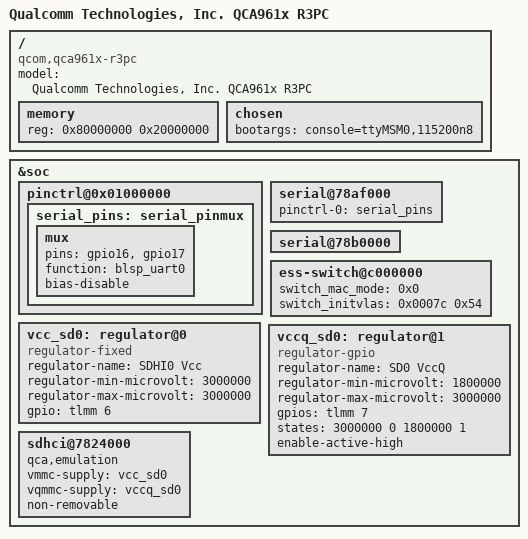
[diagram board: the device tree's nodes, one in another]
/* Copyright (c) 2014, The Linux Foundation. All rights reserved.
 *
 * This program is free software; you can redistribute it and/or modify
 * it under the terms of the GNU General Public License version 2 and
 * only version 2 as published by the Free Software Foundation.
 *
 * This program is distributed in the hope that it will be useful,
 * but WITHOUT ANY WARRANTY; without even the implied warranty of
 * MERCHANTABILITY or FITNESS FOR A PARTICULAR PURPOSE.  See the
 * GNU General Public License for more details.
 */

#include "qcom-qca961x.dtsi"
#include "qcom-qca961x-display.dtsi"
#include "qpic-panel-ili-qvga.dtsi"
#include "qcom-qca961x-hsuart.dtsi"

/ {
	model = "Qualcomm Technologies, Inc. QCA961x R3PC";
	compatible = "qcom,qca961x-r3pc", "qcom,qca961x";

	memory {
		device_type = "memory";
		reg = <0x80000000 0x20000000>; /* 512MB */
	};

	chosen {
		bootargs = "console=ttyMSM0,115200n8";
	};

};
	&soc {
		pinctrl@0x01000000 {
			serial_pins: serial_pinmux {
				mux {
					pins = "gpio16", "gpio17";
					function = "blsp_uart0";
					bias-disable;
				};
			};
		};

		serial@78af000 {
			pinctrl-0 = <&serial_pins>;
			pinctrl-names = "default";
			status = "ok";
		};

		serial@78b0000 {
			status = "ok";
		};

		ess-switch@c000000 {
			switch_mac_mode = <0x0>; /* mac mode for RGMII RMII */
			switch_initvlas = <
				0x0007c 0x54     /* PORT0_STATUS */
			>;
		};

		vcc_sd0: regulator@0 {
			compatible = "regulator-fixed";
			regulator-name = "SDHI0 Vcc";
			regulator-min-microvolt = <3000000>;
			regulator-max-microvolt = <3000000>;
			gpio = <&tlmm 6 0>;
		};

		vccq_sd0: regulator@1 {
			compatible = "regulator-gpio";
			regulator-name = "SD0 VccQ";
			regulator-min-microvolt = <1800000>;
			regulator-max-microvolt = <3000000>;

			gpios = <&tlmm 7 0>;
			states = <3000000 0
				1800000 1>;
			enable-active-high;
		};

		sdhci@7824000 {
			qca,emulation;
			status = "ok";
			vmmc-supply = <&vcc_sd0>;
			vqmmc-supply = <&vccq_sd0>;
			non-removable;
		};
	};
